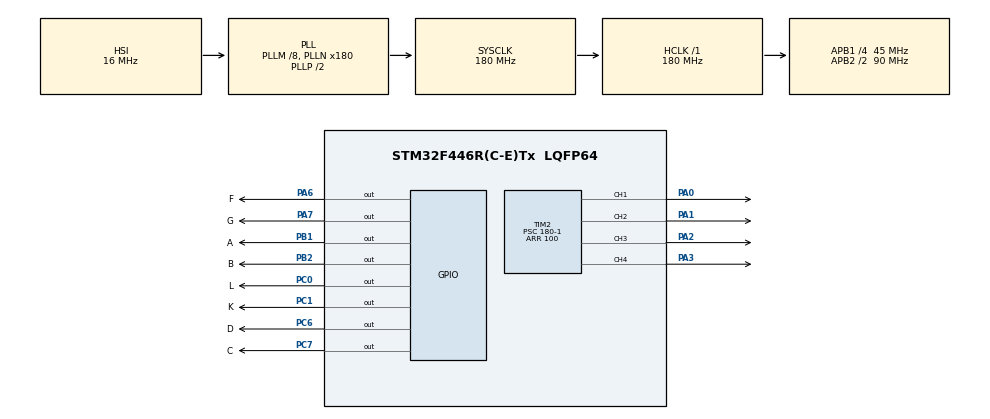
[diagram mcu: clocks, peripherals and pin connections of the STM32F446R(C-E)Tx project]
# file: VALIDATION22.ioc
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Mcu.Family=STM32F4
Mcu.Name=STM32F446R(C-E)Tx
Mcu.Package=LQFP64
NVIC.PriorityGroup=NVIC_PRIORITYGROUP_0
PA0-WKUP.GPIO_PuPd=GPIO_PULLDOWN
PA0-WKUP.Signal=S_TIM2_CH1_ETR
PA1.Signal=S_TIM2_CH2
PA2.Signal=S_TIM2_CH3
PA3.Signal=S_TIM2_CH4
PA6.GPIO_Label=F
PA6.GPIO_PuPd=GPIO_PULLDOWN
PA6.Signal=GPIO_Output
PA7.GPIO_Label=G
PA7.GPIO_PuPd=GPIO_PULLDOWN
PA7.Signal=GPIO_Output
PB1.GPIO_Label=A
PB1.GPIO_PuPd=GPIO_PULLDOWN
PB1.Signal=GPIO_Output
PB2.GPIO_Label=B
PB2.GPIO_PuPd=GPIO_PULLDOWN
PB2.Signal=GPIO_Output
PC0.GPIO_Label=L
PC0.GPIO_PuPd=GPIO_PULLDOWN
PC0.GPIO_Speed=GPIO_SPEED_FREQ_MEDIUM
PC0.Signal=GPIO_Output
PC1.GPIO_Label=K
PC1.GPIO_PuPd=GPIO_PULLDOWN
PC1.GPIO_Speed=GPIO_SPEED_FREQ_MEDIUM
PC1.Signal=GPIO_Output
PC6.GPIO_Label=D
PC6.GPIO_PuPd=GPIO_PULLDOWN
PC6.GPIO_Speed=GPIO_SPEED_FREQ_MEDIUM
PC6.Signal=GPIO_Output
PC7.GPIO_Label=C
PC7.GPIO_PuPd=GPIO_PULLDOWN
PC7.GPIO_Speed=GPIO_SPEED_FREQ_MEDIUM
PC7.Signal=GPIO_Output
ProjectManager.HeapSize=0x200
ProjectManager.StackSize=0x400
ProjectManager.TargetToolchain=STM32CubeIDE
RCC.48MHZClocksFreq_Value=84000000
RCC.AHBFreq_Value=180000000
RCC.APB1CLKDivider=RCC_HCLK_DIV4
RCC.APB1Freq_Value=45000000
RCC.APB1TimFreq_Value=90000000
RCC.APB2CLKDivider=RCC_HCLK_DIV2
RCC.APB2Freq_Value=90000000
RCC.APB2TimFreq_Value=180000000
RCC.CortexFreq_Value=180000000
RCC.FLatency-AdvancedSettings=FLASH_LATENCY_5
RCC.HCLKFreq_Value=180000000
RCC.HSE_VALUE=8000000
RCC.HSI_VALUE=16000000
RCC.PLLM=8
RCC.PLLN=180
RCC.SYSCLKFreq_VALUE=180000000
RCC.SYSCLKSource=RCC_SYSCLKSOURCE_PLLCLK
RCC.USBFreq_Value=180000000
RCC.VCOOutputFreq_Value=360000000
SH.S_TIM2_CH1_ETR.0=TIM2_CH1,PWM Generation1 CH1
SH.S_TIM2_CH2.0=TIM2_CH2,PWM Generation2 CH2
SH.S_TIM2_CH3.0=TIM2_CH3,PWM Generation3 CH3
SH.S_TIM2_CH4.0=TIM2_CH4,Output Compare4 CH4
TIM2.Channel-Output\ Compare4\ CH4=TIM_CHANNEL_4
TIM2.Channel-PWM\ Generation1\ CH1=TIM_CHANNEL_1
TIM2.Channel-PWM\ Generation2\ CH2=TIM_CHANNEL_2
TIM2.Channel-PWM\ Generation3\ CH3=TIM_CHANNEL_3
TIM2.Period=100
TIM2.Prescaler=180-1
VP_TIM2_VS_ClockSourceINT.Mode=Internal
board=NUCLEO-F446RE

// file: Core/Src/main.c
/* USER CODE BEGIN Header */
/**
  ******************************************************************************
  * @file           : main.c
  * @brief          : Main program body
  ******************************************************************************
  * @attention
  *
  * Copyright (c) 2024 STMicroelectronics.
  * All rights reserved.
  *
  * This software is licensed under terms that can be found in the LICENSE file
  * in the root directory of this software component.
  * If no LICENSE file comes with this software, it is provided AS-IS.
  *
  ******************************************************************************
  */
/* USER CODE END Header */
#include "main.h"

TIM_HandleTypeDef htim2;

void SystemClock_Config(void);
static void MX_GPIO_Init(void);
static void MX_TIM2_Init(void);

int main(void)
{

  /* MCU Configuration--------------------------------------------------------*/

  /* Reset of all peripherals, Initializes the Flash interface and the Systick. */
  HAL_Init();

  /* Configure the system clock */
  SystemClock_Config();

  /* Initialize all configured peripherals */
  MX_GPIO_Init();
  MX_TIM2_Init();
  /* USER CODE BEGIN 2 */
  HAL_TIM_PWM_Start(&htim2, TIM_CHANNEL_1);//MT1
  HAL_TIM_PWM_Start(&htim2, TIM_CHANNEL_2);//MT1
  HAL_TIM_PWM_Start(&htim2, TIM_CHANNEL_3);//MT1
  HAL_TIM_PWM_Start(&htim2, TIM_CHANNEL_4);//MT1

  /* USER CODE END 2 */

  /* Infinite loop */
  while (1)
  {

    /* USER CODE BEGIN 3 */

		 HAL_GPIO_WritePin(GPIOC,  K_Pin, SET);
		 HAL_GPIO_WritePin(GPIOC,   L_Pin, RESET);
		  TIM2->CCR1=70;
		HAL_Delay(10000);

  }
  /* USER CODE END 3 */
}

void SystemClock_Config(void)
{
  RCC_OscInitTypeDef RCC_OscInitStruct = {0};
  RCC_ClkInitTypeDef RCC_ClkInitStruct = {0};

  /** Configure the main internal regulator output voltage
  */
  __HAL_RCC_PWR_CLK_ENABLE();
  __HAL_PWR_VOLTAGESCALING_CONFIG(PWR_REGULATOR_VOLTAGE_SCALE1);

  /** Initializes the RCC Oscillators according to the specified parameters
  * in the RCC_OscInitTypeDef structure.
  */
  RCC_OscInitStruct.OscillatorType = RCC_OSCILLATORTYPE_HSI;
  RCC_OscInitStruct.HSIState = RCC_HSI_ON;
  RCC_OscInitStruct.HSICalibrationValue = RCC_HSICALIBRATION_DEFAULT;
  RCC_OscInitStruct.PLL.PLLState = RCC_PLL_ON;
  RCC_OscInitStruct.PLL.PLLSource = RCC_PLLSOURCE_HSI;
  RCC_OscInitStruct.PLL.PLLM = 8;
  RCC_OscInitStruct.PLL.PLLN = 180;
  RCC_OscInitStruct.PLL.PLLP = RCC_PLLP_DIV2;
  RCC_OscInitStruct.PLL.PLLQ = 2;
  RCC_OscInitStruct.PLL.PLLR = 2;
  if (HAL_RCC_OscConfig(&RCC_OscInitStruct) != HAL_OK)
  {
    Error_Handler();
  }

  /** Activate the Over-Drive mode
  */
  if (HAL_PWREx_EnableOverDrive() != HAL_OK)
  {
    Error_Handler();
  }

  /** Initializes the CPU, AHB and APB buses clocks
  */
  RCC_ClkInitStruct.ClockType = RCC_CLOCKTYPE_HCLK|RCC_CLOCKTYPE_SYSCLK
                              |RCC_CLOCKTYPE_PCLK1|RCC_CLOCKTYPE_PCLK2;
  RCC_ClkInitStruct.SYSCLKSource = RCC_SYSCLKSOURCE_PLLCLK;
  RCC_ClkInitStruct.AHBCLKDivider = RCC_SYSCLK_DIV1;
  RCC_ClkInitStruct.APB1CLKDivider = RCC_HCLK_DIV4;
  RCC_ClkInitStruct.APB2CLKDivider = RCC_HCLK_DIV2;

  if (HAL_RCC_ClockConfig(&RCC_ClkInitStruct, FLASH_LATENCY_5) != HAL_OK)
  {
    Error_Handler();
  }
}

static void MX_TIM2_Init(void)
{

  TIM_ClockConfigTypeDef sClockSourceConfig = {0};
  TIM_MasterConfigTypeDef sMasterConfig = {0};
  TIM_OC_InitTypeDef sConfigOC = {0};

  htim2.Instance = TIM2;
  htim2.Init.Prescaler = 90-1;
  htim2.Init.CounterMode = TIM_COUNTERMODE_UP;
  htim2.Init.Period = 100;
  htim2.Init.ClockDivision = TIM_CLOCKDIVISION_DIV1;
  htim2.Init.AutoReloadPreload = TIM_AUTORELOAD_PRELOAD_DISABLE;
  if (HAL_TIM_Base_Init(&htim2) != HAL_OK)
  {
    Error_Handler();
  }
  sClockSourceConfig.ClockSource = TIM_CLOCKSOURCE_INTERNAL;
  if (HAL_TIM_ConfigClockSource(&htim2, &sClockSourceConfig) != HAL_OK)
  {
    Error_Handler();
  }
  if (HAL_TIM_PWM_Init(&htim2) != HAL_OK)
  {
    Error_Handler();
  }
  if (HAL_TIM_OC_Init(&htim2) != HAL_OK)
  {
    Error_Handler();
  }
  sMasterConfig.MasterOutputTrigger = TIM_TRGO_RESET;
  sMasterConfig.MasterSlaveMode = TIM_MASTERSLAVEMODE_DISABLE;
  if (HAL_TIMEx_MasterConfigSynchronization(&htim2, &sMasterConfig) != HAL_OK)
  {
    Error_Handler();
  }
  sConfigOC.OCMode = TIM_OCMODE_PWM1;
  sConfigOC.Pulse = 0;
  sConfigOC.OCPolarity = TIM_OCPOLARITY_HIGH;
  sConfigOC.OCFastMode = TIM_OCFAST_DISABLE;
  if (HAL_TIM_PWM_ConfigChannel(&htim2, &sConfigOC, TIM_CHANNEL_1) != HAL_OK)
  {
    Error_Handler();
  }
  if (HAL_TIM_PWM_ConfigChannel(&htim2, &sConfigOC, TIM_CHANNEL_2) != HAL_OK)
  {
    Error_Handler();
  }
  if (HAL_TIM_PWM_ConfigChannel(&htim2, &sConfigOC, TIM_CHANNEL_3) != HAL_OK)
  {
    Error_Handler();
  }
  sConfigOC.OCMode = TIM_OCMODE_TIMING;
  if (HAL_TIM_OC_ConfigChannel(&htim2, &sConfigOC, TIM_CHANNEL_4) != HAL_OK)
  {
    Error_Handler();
  }
  HAL_TIM_MspPostInit(&htim2);

}

static void MX_GPIO_Init(void)
{
  GPIO_InitTypeDef GPIO_InitStruct = {0};

  /* GPIO Ports Clock Enable */
  __HAL_RCC_GPIOC_CLK_ENABLE();
  __HAL_RCC_GPIOA_CLK_ENABLE();
  __HAL_RCC_GPIOB_CLK_ENABLE();

  /*Configure GPIO pin Output Level */
  HAL_GPIO_WritePin(GPIOC, L_Pin|K_Pin|D_Pin|C_Pin, GPIO_PIN_RESET);

  /*Configure GPIO pin Output Level */
  HAL_GPIO_WritePin(GPIOA, F_Pin|G_Pin, GPIO_PIN_RESET);

  /*Configure GPIO pin Output Level */
  HAL_GPIO_WritePin(GPIOB, A_Pin|B_Pin, GPIO_PIN_RESET);

  /*Configure GPIO pins : L_Pin K_Pin D_Pin C_Pin */
  GPIO_InitStruct.Pin = L_Pin|K_Pin|D_Pin|C_Pin;
  GPIO_InitStruct.Mode = GPIO_MODE_OUTPUT_PP;
  GPIO_InitStruct.Pull = GPIO_PULLDOWN;
  GPIO_InitStruct.Speed = GPIO_SPEED_FREQ_MEDIUM;
  HAL_GPIO_Init(GPIOC, &GPIO_InitStruct);

  /*Configure GPIO pins : F_Pin G_Pin */
  GPIO_InitStruct.Pin = F_Pin|G_Pin;
  GPIO_InitStruct.Mode = GPIO_MODE_OUTPUT_PP;
  GPIO_InitStruct.Pull = GPIO_PULLDOWN;
  GPIO_InitStruct.Speed = GPIO_SPEED_FREQ_LOW;
  HAL_GPIO_Init(GPIOA, &GPIO_InitStruct);

  /*Configure GPIO pins : A_Pin B_Pin */
  GPIO_InitStruct.Pin = A_Pin|B_Pin;
  GPIO_InitStruct.Mode = GPIO_MODE_OUTPUT_PP;
  GPIO_InitStruct.Pull = GPIO_PULLDOWN;
  GPIO_InitStruct.Speed = GPIO_SPEED_FREQ_LOW;
  HAL_GPIO_Init(GPIOB, &GPIO_InitStruct);

}

void Error_Handler(void)
{
  __disable_irq();
  while (1)
  {
  }
}
